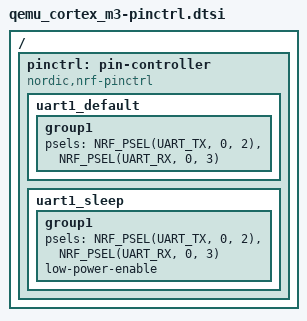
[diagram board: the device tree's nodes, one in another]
/* Since the QEMU device tree uses a UART device that does not have
 * tx-pin and rx-pin properties, we override that with this custom peripheral
 * that inherits from nordic,nrf-uarte which has the properties.
 * These properties are used by the unit under test.
 */
#include <zephyr/dt-bindings/pinctrl/nrf-pinctrl.h>

/ {
        pinctrl: pin-controller {
                /* Pin controller is a "virtual" device since nRF SoCs do pin
                 * control in a distributed way (GPIO registers and PSEL
                 * registers on each peripheral).
                 */
                compatible = "nordic,nrf-pinctrl";
        };

};

&pinctrl {
	uart1_default: uart1_default {
		group1 {
			psels = <NRF_PSEL(UART_TX, 0, 2)>,
				<NRF_PSEL(UART_RX, 0, 3)>;
		};
	};

	uart1_sleep: uart1_sleep {
		group1 {
			psels = <NRF_PSEL(UART_TX, 0, 2)>,
				<NRF_PSEL(UART_RX, 0, 3)>;
			low-power-enable;
		};
	};
};
